# ZB32L030 register map
Vendor: ZBit.; Series: ZB32L03X; File version: 1.0
ARM 32-bit Cortex-M0+ Microcontroller based device, CPU clock up to 24MHz, etc.
CPU: CM0+ r1p0, little endian, no MPU, no FPU, VTOR, 2 interrupt priority bits
Registers are 32-bit, read-write, reset 0x0 unless marked. A register's access mark holds for its fields unless they carry their own. Offsets are from the block's base; lines under a group give offsets from that group; [hi:lo] are bit positions; {n}, {i} and the like mark numbered series; 'fields as' and 'values as' point back to an identical list; <NAME> marks a mode.

## Memory map
0x00000000 MMP_ALIAS size 0xC — Memory mapping
0x00000000 EFLASH_MEM size 0xC
0x08000000 OBYTES size 0x200 — Option Bytes as user configuration
0x18000000 SYSCFG size 0x100 — system configuration of NVR
0x180000F0 DEV_UID size 0xC
0x20000000 ESRAM_MEM size 0xC
0x40000000 UART size 0x20
0x40000000 UART0 size 0x20
0x40000200 UART2 size 0x20
0x40000400 UART1 size 0x20
0x40000600 UART3 size 0x20
0x40000800 SPI size 0x10
0x40000800 SPI0 size 0x10
0x40000A00 SPI1 size 0x10
0x40000C00 I2C size 0x18
0x40000C00 I2C0 size 0x18
0x40000E00 I2C1 size 0x18
0x40001000 TIM size 0x48 — Advance Timer
0x40001000 TIM1 size 0x48
0x40001200 TIM1A size 0x48
0x40001300 TIM1B size 0x48
0x40001400 PCA size 0x74 — Programmable Counter Array
0x40001800 BASETIM size 0x1C — BASE TIMER
0x40001800 TIM10 size 0x1C
0x40001900 TIM11 size 0x1C
0x40001C00 SYSCON size 0x54 — system control config
0x40002000 WWDG size 0x18 — Window Watch Dog
0x40002400 IWDG size 0x1C — Independ Watch Dog
0x40002800 AWK size 0x10 — Auto wake
0x40002C00 ADC size 0x54
0x40003000 RTC size 0x2C
0x40003400 CLKTRIM size 0x1C
0x40003800 OWIRE size 0x34 — One Wire
0x40003C00 TIM2 size 0x48
0x40003D00 TIM2A size 0x48
0x40003E00 TIM2B size 0x48
0x40003F00 TIM2C size 0x48
0x40004000 LVD size 0x8
0x40004080 VC size 0x10 — Voltage Comparator
0x40004080 VC0 size 0x10
0x40004100 VC1 size 0x10 — Voltage Comparator
0x40004400 LPTIM size 0x18 — Low Power Timer
0x40004800 BEEP size 0x4
0x40004C00 DBG size 0x4 — Debug MCU
0x40005000 LPUART size 0x20 — Low Power UART Register
0x40005400 OPA size 0xC — Operational Amplifier
0x40020000 RCC size 0x64 — Reset and Clock Control
0x40020400 FLASH size 0x40 — Flash Controller
0x40020800 CRC size 0x100
0x40021000 GPIO size 0x50 — GPIO register list
0x40021000 GPIOA size 0x50
0x40021400 GPIOB size 0x50
0x40021800 GPIOC size 0x50
0x40021C00 GPIOD size 0x50

## Interrupts
0 GPIOA (GPIO, GPIOA)
1 GPIOB — GPIOB global interrupt
2 GPIOC — GPIOC global interrupt
3 GPIOD — GPIOD global interrupt
4 FLASH — Flash interrupt
6 UART0 (UART, UART0)
7 UART1 — UART1 global interrupt
8 LPUART
9 UART2_3 (UART2, UART3) — UART2 global interrupt
10 SPI0_1 (SPI, SPI0, SPI1)
11 TIM2C — TIM2C global interrupt
12 I2C0_1 (I2C, I2C0, I2C1)
13 TIM1B — TIM1B global interrupt
14 TIM10 (BASETIM, TIM10)
15 TIM11 — TIM11 global interrupt
16 LPTIM
17 TIM1A — TIM1A global interrupt
18 TIM1 (TIM, TIM1)
19 TIM2 — TIM2 global interrupt
20 TIM2A — TIM2A global interrupt
21 PCA
22 WWDG
23 IWDG
24 ADC
25 LVD
26 VC0_1 (VC, VC0, VC1)
27 TIM2B — TIM2B global interrupt
28 AWK
29 OWIRE
30 RTC
31 CLKTRIM

## MMP_ALIAS — Memory mapping
Base 0x00000000
Same registers: EFLASH_MEM 0x00000000, DEV_UID 0x180000F0, ESRAM_MEM 0x20000000
0x00 DATA0 — The first address

## OPA — Operational Amplifier
Base 0x40005400
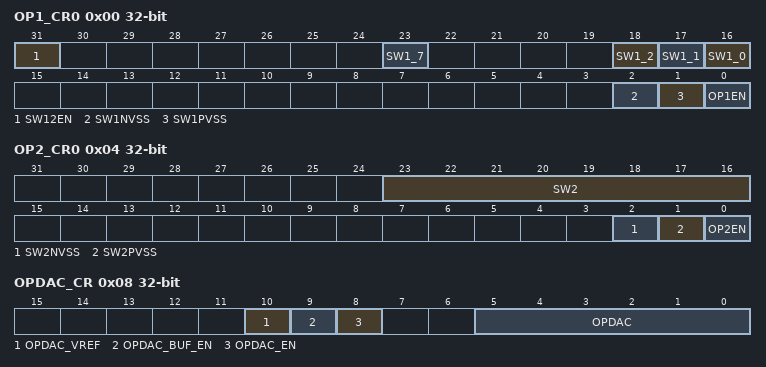
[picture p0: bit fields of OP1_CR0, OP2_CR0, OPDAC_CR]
0x00 OP1_CR0 — OP1 Control Register 0
  [31] SW12EN — OP1 output to OP2 input
  [23] SW1_7 — OP1 select configuration
  [18] SW1_2 — OP1 select configuration
  [17] SW1_1 — OP1 select configuration
  [16] SW1_0 — OP1 select configuration
  [2] SW1NVSS — OP1 VN short to VSS
  [1] SW1PVSS — OP1 VP short to VSS
  [0] OP1EN — OP1 Enable
0x04 OP2_CR0 — OP2 Control Register 0
  [23:16] SW2 — OP2 select configuration
  [2] SW2NVSS — OP2 VN short to VSS
  [1] SW2PVSS — OP2 VP short to VSS
  [0] OP2EN — OP2 Enable
0x08 OPDAC_CR — DAC (OP1/OP2) Contorl Registet
  [10] OPDAC_VREF — OPA DAC reference voltage select
  [9] OPDAC_BUF_EN — OPA DAC buffer control Enable
  [8] OPDAC_EN — OPA DAC control Enable
  [5:0] OPDAC — Enable OPA use DAC_C0O voltage output

## Licence text in the file
CMSIS Cortex-M+ Device Peripheral Access Layer Header File. This file contains all the peripheral register's definitions, bits definitions and memory mapping for ZB32L03x devices. . This file contains: - Data structures and the address mapping for all peripherals - Peripheral's registers declarations and bits definition

## Notices in the file
Copyright (C) 2012 ARM Limited. All rights reserved.
Purpose: System Viewer Description (SVD) Example (Schema Version 1.1)
This is a description of a none-existent and incomplete device
for demonstration purposes only.
Redistribution and use in source and binary forms, with or without
modification, are permitted provided that the following conditions are met:
- Redistributions of source code must retain the above copyright
notice, this list of conditions and the following disclaimer.
- Redistributions in binary form must reproduce the above copyright
notice, this list of conditions and the following disclaimer in the
documentation and/or other materials provided with the distribution.
- Neither the name of ARM nor the names of its contributors may be used
to endorse or promote products derived from this software without
specific prior written permission.
THIS SOFTWARE IS PROVIDED BY THE COPYRIGHT HOLDERS AND CONTRIBUTORS "AS IS"
AND ANY EXPRESS OR IMPLIED WARRANTIES, INCLUDING, BUT NOT LIMITED TO, THE
IMPLIED WARRANTIES OF MERCHANTABILITY AND FITNESS FOR A PARTICULAR PURPOSE
ARE DISCLAIMED. IN NO EVENT SHALL COPYRIGHT HOLDERS AND CONTRIBUTORS BE
LIABLE FOR ANY DIRECT, INDIRECT, INCIDENTAL, SPECIAL, EXEMPLARY, OR
CONSEQUENTIAL DAMAGES (INCLUDING, BUT NOT LIMITED TO, PROCUREMENT OF
SUBSTITUTE GOODS OR SERVICES; LOSS OF USE, DATA, OR PROFITS; OR BUSINESS
INTERRUPTION) HOWEVER CAUSED AND ON ANY THEORY OF LIABILITY, WHETHER IN
CONTRACT, STRICT LIABILITY, OR TORT (INCLUDING NEGLIGENCE OR OTHERWISE)
ARISING IN ANY WAY OUT OF THE USE OF THIS SOFTWARE, EVEN IF ADVISED OF THE
POSSIBILITY OF SUCH DAMAGE.
